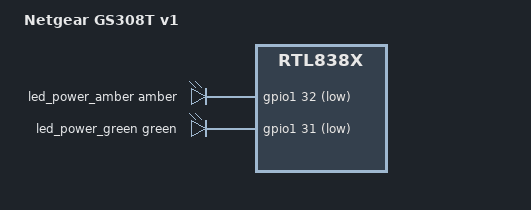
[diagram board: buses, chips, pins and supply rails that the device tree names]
// SPDX-License-Identifier: GPL-2.0-or-later

#include "rtl8380_netgear_gigabit.dtsi"

/ {
	compatible = "netgear,gs308t-v1", "realtek,rtl838x-soc";
	model = "Netgear GS308T v1";

	aliases {
		led-boot = &led_power_green;
		led-failsafe = &led_power_amber;
		led-running = &led_power_green;
		led-upgrade = &led_power_amber;
	};

	leds {
		compatible = "gpio-leds";

		led_power_amber: led-0 {
			color = <LED_COLOR_ID_AMBER>;
			function = LED_FUNCTION_POWER;
			gpios = <&gpio1 32 GPIO_ACTIVE_LOW>;
		};

		led_power_green: led-1 {
			color = <LED_COLOR_ID_GREEN>;
			function = LED_FUNCTION_POWER;
			gpios = <&gpio1 31 GPIO_ACTIVE_LOW>;
		};
	};
};

&firmware {
	openwrt,ih-magic = <0x4e474335>;
};

&switch0 {
	port-leds {
		led-control-mode = <RTL838X_LEDS_CONTROL_MODE_SERIAL>;
	};
};

#define SWITCH_PORT_LEDS(port) \
	SWITCH_PORT_LED(##port,0, RTL838X_LEDS_TRIGGER_LINK_ACT_1G, LED_COLOR_ID_GREEN) \
	SWITCH_PORT_LED(##port,1, RTL838X_LEDS_TRIGGER_LINK_ACT_100M_10M, LED_COLOR_ID_AMBER)

SWITCH_PORT_LEDS(8)
SWITCH_PORT_LEDS(9)
SWITCH_PORT_LEDS(10)
SWITCH_PORT_LEDS(11)
SWITCH_PORT_LEDS(12)
SWITCH_PORT_LEDS(13)
SWITCH_PORT_LEDS(14)
SWITCH_PORT_LEDS(15)
